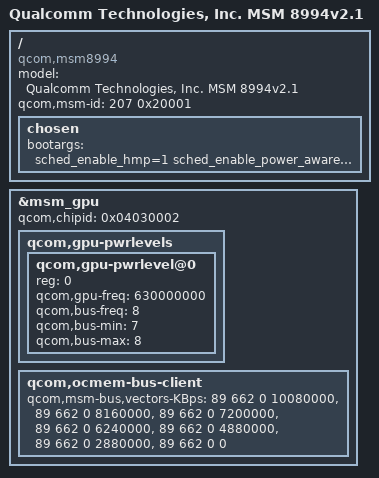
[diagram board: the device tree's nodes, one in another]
/* Copyright (c) 2014-2015, The Linux Foundation. All rights reserved.
 *
 * This program is free software; you can redistribute it and/or modify
 * it under the terms of the GNU General Public License version 2 and
 * only version 2 as published by the Free Software Foundation.
 *
 * This program is distributed in the hope that it will be useful,
 * but WITHOUT ANY WARRANTY; without even the implied warranty of
 * MERCHANTABILITY or FITNESS FOR A PARTICULAR PURPOSE.  See the
 * GNU General Public License for more details.
 */

/*
 * As a general rule, only version-specific property overrides should be placed
 * inside this file. Device definitions should be placed inside the msm8994.dtsi
 * file.
 */

#include "msm8994-v2.dtsi"

/ {
	model = "Qualcomm Technologies, Inc. MSM 8994v2.1";
	compatible = "qcom,msm8994";
	qcom,msm-id = <207 0x20001>;

	chosen {
		bootargs = "sched_enable_hmp=1 sched_enable_power_aware=1";
	};
};

/* GPU overrides */
&msm_gpu {
	/* Updated chip ID */
	qcom,chipid = <0x04030002>;
	qcom,gpu-pwrlevels {
		qcom,gpu-pwrlevel@0 {
			reg = <0>;
			qcom,gpu-freq = <630000000>;
			qcom,bus-freq = <8>;
			qcom,bus-min = <7>;
			qcom,bus-max = <8>;
		};
	};
	qcom,ocmem-bus-client {
		qcom,msm-bus,vectors-KBps =
			<89 662 0 10080000>, /* gpu= 630 */
			<89 662 0  8160000>, /* gpu= 510 */
			<89 662 0  7200000>, /* gpu= 450 */
			<89 662 0  6240000>, /* gpu= 390 */
			<89 662 0  4880000>, /* gpu= 305 */
			<89 662 0  2880000>, /* gpu= 180 */
			<89 662 0 0>;
	};
};
